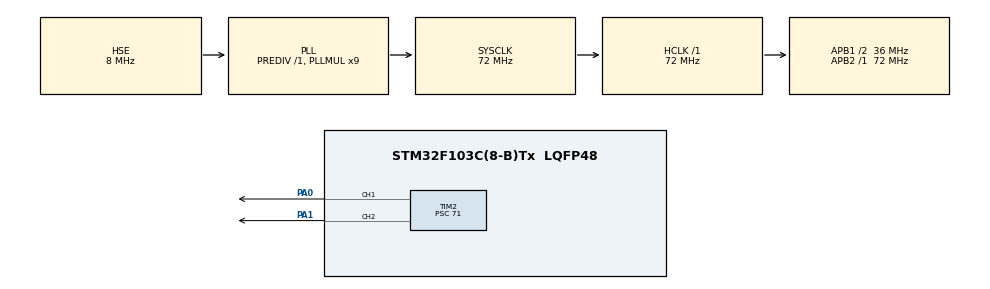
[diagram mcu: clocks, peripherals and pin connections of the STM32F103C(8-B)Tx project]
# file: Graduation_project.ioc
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Mcu.Family=STM32F1
Mcu.Name=STM32F103C(8-B)Tx
Mcu.Package=LQFP48
NVIC.PriorityGroup=NVIC_PRIORITYGROUP_4
PA0-WKUP.Signal=S_TIM2_CH1_ETR
PA1.Signal=S_TIM2_CH2
PA13.Mode=Serial_Wire
PA13.Signal=SYS_JTMS-SWDIO
PA14.Mode=Serial_Wire
PA14.Signal=SYS_JTCK-SWCLK
PC14-OSC32_IN.Mode=LSE-External-Oscillator
PC14-OSC32_IN.Signal=RCC_OSC32_IN
PC15-OSC32_OUT.Mode=LSE-External-Oscillator
PC15-OSC32_OUT.Signal=RCC_OSC32_OUT
PD0-OSC_IN.Mode=HSE-External-Oscillator
PD0-OSC_IN.Signal=RCC_OSC_IN
PD1-OSC_OUT.Mode=HSE-External-Oscillator
PD1-OSC_OUT.Signal=RCC_OSC_OUT
ProjectManager.HeapSize=0x200
ProjectManager.StackSize=0x400
ProjectManager.TargetToolchain=MDK-ARM V5.32
RCC.AHBFreq_Value=72000000
RCC.APB1CLKDivider=RCC_HCLK_DIV2
RCC.APB1Freq_Value=36000000
RCC.APB1TimFreq_Value=72000000
RCC.APB2Freq_Value=72000000
RCC.APB2TimFreq_Value=72000000
RCC.HCLKFreq_Value=72000000
RCC.HSE_Timout=100
RCC.PLLMUL=RCC_PLL_MUL9
RCC.PLLSourceVirtual=RCC_PLLSOURCE_HSE
RCC.SYSCLKFreq_VALUE=72000000
RCC.SYSCLKSource=RCC_SYSCLKSOURCE_PLLCLK
RCC.USBFreq_Value=72000000
SH.S_TIM2_CH1_ETR.0=TIM2_CH1,PWM Generation1 CH1
SH.S_TIM2_CH2.0=TIM2_CH2,PWM Generation2 CH2
TIM2.Channel-PWM\ Generation1\ CH1=TIM_CHANNEL_1
TIM2.Channel-PWM\ Generation2\ CH2=TIM_CHANNEL_2
TIM2.Period=20000
TIM2.Prescaler=71
VP_TIM2_VS_ClockSourceINT.Mode=Internal
board=custom

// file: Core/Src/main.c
/* USER CODE BEGIN Header */
/**
  ******************************************************************************
  * @file           : main.c
  * @brief          : Main program body
  ******************************************************************************
  * @attention
  *
  * Copyright (c) 2026 STMicroelectronics.
  * All rights reserved.
  *
  * This software is licensed under terms that can be found in the LICENSE file
  * in the root directory of this software component.
  * If no LICENSE file comes with this software, it is provided AS-IS.
  *
  ******************************************************************************
  */
/* USER CODE END Header */
#include "main.h"
#include "tim.h"
#include "gpio.h"

void SystemClock_Config(void);

/* USER CODE BEGIN 0 */
/**
 * @brief  控制MG996R舵机转动到指定角度
 * @param  htim: 定时器句柄指针 (例如 &htim2)
 * @param  channel: 定时器通道 (例如 TIM_CHANNEL_1)
 * @param  angle: 目标角度 (0 ~ 180度)
 * @retval 无
 */
void Servo_SetAngle(TIM_HandleTypeDef *htim, uint32_t channel, uint8_t angle)
{
    // 限制角度范围，防止超出机械限位
    if(angle > 180) angle = 180;

    // 计算PWM脉宽值
    // 0度 = 0.5ms (500个计数值)
    // 180度 = 2.5ms (2500个计数值)
    // 计算公式: Pulse = 500 + (angle * 2000 / 180)
    uint16_t pulse_width = 500 + (uint16_t)((angle * 2000) / 180);

    // 设置比较寄存器值
    __HAL_TIM_SET_COMPARE(htim, channel, pulse_width);
}

/* USER CODE END 0 */

int main(void)
{

  /* MCU Configuration--------------------------------------------------------*/

  /* Reset of all peripherals, Initializes the Flash interface and the Systick. */
  HAL_Init();

  /* Configure the system clock */
  SystemClock_Config();

  /* Initialize all configured peripherals */
  MX_GPIO_Init();
  MX_TIM2_Init();
  /* USER CODE BEGIN 2 */
// 启动定时器PWM通道输出
  HAL_TIM_PWM_Start(&htim2, TIM_CHANNEL_1);

      // 回到中间
      Servo_SetAngle(&htim2, TIM_CHANNEL_1, 90);
      HAL_Delay(1000);

      // 可以在这里加入更细腻的测试，比如每次转1度
      /*
      for(uint8_t i=0; i<=180; i++){
          Servo_SetAngle(&htim2, TIM_CHANNEL_1, i);
          HAL_Delay(10);
      }
      */
  }

void SystemClock_Config(void)
{
  RCC_OscInitTypeDef RCC_OscInitStruct = {0};
  RCC_ClkInitTypeDef RCC_ClkInitStruct = {0};

  /** Initializes the RCC Oscillators according to the specified parameters
  * in the RCC_OscInitTypeDef structure.
  */
  RCC_OscInitStruct.OscillatorType = RCC_OSCILLATORTYPE_HSE;
  RCC_OscInitStruct.HSEState = RCC_HSE_ON;
  RCC_OscInitStruct.HSEPredivValue = RCC_HSE_PREDIV_DIV1;
  RCC_OscInitStruct.HSIState = RCC_HSI_ON;
  RCC_OscInitStruct.PLL.PLLState = RCC_PLL_ON;
  RCC_OscInitStruct.PLL.PLLSource = RCC_PLLSOURCE_HSE;
  RCC_OscInitStruct.PLL.PLLMUL = RCC_PLL_MUL9;
  if (HAL_RCC_OscConfig(&RCC_OscInitStruct) != HAL_OK)
  {
    Error_Handler();
  }

  /** Initializes the CPU, AHB and APB buses clocks
  */
  RCC_ClkInitStruct.ClockType = RCC_CLOCKTYPE_HCLK|RCC_CLOCKTYPE_SYSCLK
                              |RCC_CLOCKTYPE_PCLK1|RCC_CLOCKTYPE_PCLK2;
  RCC_ClkInitStruct.SYSCLKSource = RCC_SYSCLKSOURCE_PLLCLK;
  RCC_ClkInitStruct.AHBCLKDivider = RCC_SYSCLK_DIV1;
  RCC_ClkInitStruct.APB1CLKDivider = RCC_HCLK_DIV2;
  RCC_ClkInitStruct.APB2CLKDivider = RCC_HCLK_DIV1;

  if (HAL_RCC_ClockConfig(&RCC_ClkInitStruct, FLASH_LATENCY_2) != HAL_OK)
  {
    Error_Handler();
  }
}

void Error_Handler(void)
{
  __disable_irq();
  while (1)
  {
  }
}
